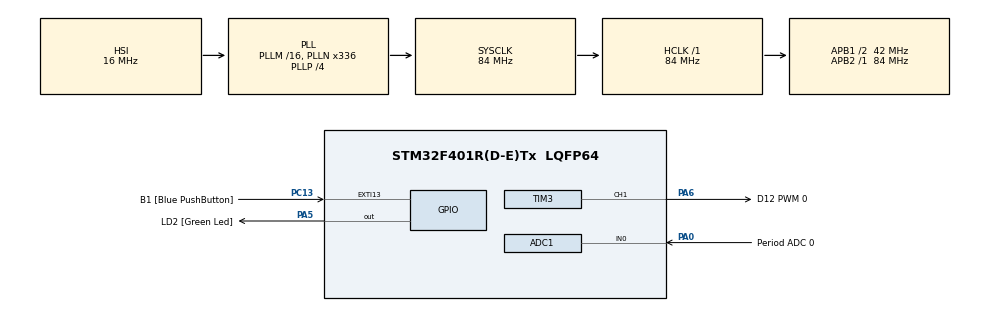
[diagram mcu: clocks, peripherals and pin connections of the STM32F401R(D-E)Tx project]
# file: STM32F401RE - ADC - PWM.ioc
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ADC1.Channel-0\#ChannelRegularConversion=ADC_CHANNEL_0
ADC1.ContinuousConvMode=ENABLE
ADC1.DMAContinuousRequests=ENABLE
ADC1.InjNumberOfConversion=0
ADC1.NbrOfConversion=1
ADC1.NbrOfConversionFlag=1
ADC1.Rank-0\#ChannelRegularConversion=1
ADC1.SamplingTime-0\#ChannelRegularConversion=ADC_SAMPLETIME_480CYCLES
ADC1.ScanConvMode=ENABLE
ADC1.master=1
Dma.ADC1.0.Direction=DMA_PERIPH_TO_MEMORY
Dma.ADC1.0.FIFOMode=DMA_FIFOMODE_DISABLE
Dma.ADC1.0.Instance=DMA2_Stream0
Dma.ADC1.0.MemDataAlignment=DMA_MDATAALIGN_WORD
Dma.ADC1.0.MemInc=DMA_MINC_ENABLE
Dma.ADC1.0.Mode=DMA_CIRCULAR
Dma.ADC1.0.PeriphDataAlignment=DMA_PDATAALIGN_WORD
Dma.ADC1.0.PeriphInc=DMA_PINC_DISABLE
Dma.ADC1.0.Priority=DMA_PRIORITY_LOW
Dma.Request0=ADC1
Mcu.Family=STM32F4
Mcu.Name=STM32F401R(D-E)Tx
Mcu.Package=LQFP64
NVIC.DMA2_Stream0_IRQn=true\:0\:0\:false\:false\:true\:false\:true
NVIC.PriorityGroup=NVIC_PRIORITYGROUP_0
PA0-WKUP.GPIO_Label=Period ADC 0
PA0-WKUP.Signal=ADCx_IN0
PA13.GPIO_Label=TMS
PA13.Signal=SYS_JTMS-SWDIO
PA14.GPIO_Label=TCK
PA14.Signal=SYS_JTCK-SWCLK
PA2.GPIO_Label=USART_TX
PA2.GPIO_Mode=GPIO_MODE_AF_PP
PA2.GPIO_PuPd=GPIO_NOPULL
PA2.GPIO_Speed=GPIO_SPEED_FREQ_LOW
PA2.Signal=USART2_TX
PA3.GPIO_Label=USART_RX
PA3.GPIO_Mode=GPIO_MODE_AF_PP
PA3.GPIO_PuPd=GPIO_NOPULL
PA3.GPIO_Speed=GPIO_SPEED_FREQ_LOW
PA3.Signal=USART2_RX
PA5.GPIO_Label=LD2 [Green Led]
PA5.GPIO_Mode=GPIO_MODE_OUTPUT_PP
PA5.GPIO_PuPd=GPIO_NOPULL
PA5.GPIO_Speed=GPIO_SPEED_FREQ_LOW
PA5.Signal=GPIO_Output
PA6.GPIO_Label=D12 PWM 0
PA6.Signal=S_TIM3_CH1
PB3.GPIO_Label=SWO
PB3.Signal=SYS_JTDO-SWO
PC13-ANTI_TAMP.GPIO_Label=B1 [Blue PushButton]
PC13-ANTI_TAMP.GPIO_ModeDefaultEXTI=GPIO_MODE_IT_FALLING
PC13-ANTI_TAMP.GPIO_PuPd=GPIO_NOPULL
PC13-ANTI_TAMP.Signal=GPXTI13
PC14-OSC32_IN.Signal=RCC_OSC32_IN
PC15-OSC32_OUT.Signal=RCC_OSC32_OUT
PH0\ -\ OSC_IN.Signal=RCC_OSC_IN
PH1\ -\ OSC_OUT.Signal=RCC_OSC_OUT
ProjectManager.HeapSize=0x200
ProjectManager.StackSize=0x400
ProjectManager.TargetToolchain=TrueSTUDIO
RCC.AHBFreq_Value=84000000
RCC.APB1CLKDivider=RCC_HCLK_DIV2
RCC.APB1Freq_Value=42000000
RCC.APB1TimFreq_Value=84000000
RCC.APB2Freq_Value=84000000
RCC.APB2TimFreq_Value=84000000
RCC.CortexFreq_Value=84000000
RCC.HCLKFreq_Value=84000000
RCC.HSE_VALUE=8000000
RCC.HSI_VALUE=16000000
RCC.LSE_VALUE=32768
RCC.PLLN=336
RCC.PLLP=RCC_PLLP_DIV4
RCC.PLLQ=7
RCC.SYSCLKFreq_VALUE=84000000
RCC.SYSCLKSource=RCC_SYSCLKSOURCE_PLLCLK
RCC.VCOOutputFreq_Value=336000000
SH.ADCx_IN0.0=ADC1_IN0,IN0
SH.S_TIM3_CH1.0=TIM3_CH1,PWM Generation1 CH1
TIM3.Channel-PWM\ Generation1\ CH1=TIM_CHANNEL_1
TIM3.Period=4095
TIM3.Prescaler=84
TIM3.Pulse-PWM\ Generation1\ CH1=2000
VP_TIM3_VS_ClockSourceINT.Mode=Internal
board=NUCLEO-F401RE

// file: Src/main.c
/* USER CODE BEGIN Header */
/**
  ******************************************************************************
  * @file           : main.c
  * @brief          : Main program body
  ******************************************************************************
  * @attention
  *
  * <h2><center>&copy; Copyright (c) 2019 STMicroelectronics.
  * All rights reserved.</center></h2>
  *
  * This software component is licensed by ST under BSD 3-Clause license,
  * the "License"; You may not use this file except in compliance with the
  * License. You may obtain a copy of the License at:
  *                        opensource.org/licenses/BSD-3-Clause
  *
  ******************************************************************************
  */
/* USER CODE END Header */

#include "main.h"

ADC_HandleTypeDef hadc1;
DMA_HandleTypeDef hdma_adc1;

TIM_HandleTypeDef htim3;

void SystemClock_Config(void);
static void MX_GPIO_Init(void);
static void MX_DMA_Init(void);
static void MX_ADC1_Init(void);
static void MX_TIM3_Init(void);

/* USER CODE BEGIN 0 */

/*
 * Store array for ADC values
 */
volatile uint32_t adcInputs[1];

/* USER CODE END 0 */

int main(void)
{

  /* MCU Configuration--------------------------------------------------------*/

  /* Reset of all peripherals, Initializes the Flash interface and the Systick. */
  HAL_Init();

  /* Configure the system clock */
  SystemClock_Config();

  /* Initialize all configured peripherals */
  MX_GPIO_Init();
  MX_DMA_Init();
  MX_ADC1_Init();
  MX_TIM3_Init();
  /* USER CODE BEGIN 2 */

  /*
   * Start all the PWM channels
   */
  HAL_TIM_PWM_Start(&htim3, TIM_CHANNEL_1);

  /*
   * Start ADC
   */
  HAL_ADC_Start_DMA(&hadc1, (uint32_t *) adcInputs, 1);

  /* USER CODE END 2 */

  /* Infinite loop */
  while (1)
  {
	  htim3.Instance->CCR1 = adcInputs[0];
  }
}

void SystemClock_Config(void)
{
  RCC_OscInitTypeDef RCC_OscInitStruct = {0};
  RCC_ClkInitTypeDef RCC_ClkInitStruct = {0};

  /** Configure the main internal regulator output voltage
  */
  __HAL_RCC_PWR_CLK_ENABLE();
  __HAL_PWR_VOLTAGESCALING_CONFIG(PWR_REGULATOR_VOLTAGE_SCALE2);
  /** Initializes the CPU, AHB and APB busses clocks
  */
  RCC_OscInitStruct.OscillatorType = RCC_OSCILLATORTYPE_HSI;
  RCC_OscInitStruct.HSIState = RCC_HSI_ON;
  RCC_OscInitStruct.HSICalibrationValue = RCC_HSICALIBRATION_DEFAULT;
  RCC_OscInitStruct.PLL.PLLState = RCC_PLL_ON;
  RCC_OscInitStruct.PLL.PLLSource = RCC_PLLSOURCE_HSI;
  RCC_OscInitStruct.PLL.PLLM = 16;
  RCC_OscInitStruct.PLL.PLLN = 336;
  RCC_OscInitStruct.PLL.PLLP = RCC_PLLP_DIV4;
  RCC_OscInitStruct.PLL.PLLQ = 7;
  if (HAL_RCC_OscConfig(&RCC_OscInitStruct) != HAL_OK)
  {
    Error_Handler();
  }
  /** Initializes the CPU, AHB and APB busses clocks
  */
  RCC_ClkInitStruct.ClockType = RCC_CLOCKTYPE_HCLK|RCC_CLOCKTYPE_SYSCLK
                              |RCC_CLOCKTYPE_PCLK1|RCC_CLOCKTYPE_PCLK2;
  RCC_ClkInitStruct.SYSCLKSource = RCC_SYSCLKSOURCE_PLLCLK;
  RCC_ClkInitStruct.AHBCLKDivider = RCC_SYSCLK_DIV1;
  RCC_ClkInitStruct.APB1CLKDivider = RCC_HCLK_DIV2;
  RCC_ClkInitStruct.APB2CLKDivider = RCC_HCLK_DIV1;

  if (HAL_RCC_ClockConfig(&RCC_ClkInitStruct, FLASH_LATENCY_2) != HAL_OK)
  {
    Error_Handler();
  }
}

static void MX_ADC1_Init(void)
{

  ADC_ChannelConfTypeDef sConfig = {0};

  /** Configure the global features of the ADC (Clock, Resolution, Data Alignment and number of conversion)
  */
  hadc1.Instance = ADC1;
  hadc1.Init.ClockPrescaler = ADC_CLOCK_SYNC_PCLK_DIV4;
  hadc1.Init.Resolution = ADC_RESOLUTION_12B;
  hadc1.Init.ScanConvMode = ENABLE;
  hadc1.Init.ContinuousConvMode = ENABLE;
  hadc1.Init.DiscontinuousConvMode = DISABLE;
  hadc1.Init.ExternalTrigConvEdge = ADC_EXTERNALTRIGCONVEDGE_NONE;
  hadc1.Init.ExternalTrigConv = ADC_SOFTWARE_START;
  hadc1.Init.DataAlign = ADC_DATAALIGN_RIGHT;
  hadc1.Init.NbrOfConversion = 1;
  hadc1.Init.DMAContinuousRequests = ENABLE;
  hadc1.Init.EOCSelection = ADC_EOC_SINGLE_CONV;
  if (HAL_ADC_Init(&hadc1) != HAL_OK)
  {
    Error_Handler();
  }
  /** Configure for the selected ADC regular channel its corresponding rank in the sequencer and its sample time.
  */
  sConfig.Channel = ADC_CHANNEL_0;
  sConfig.Rank = 1;
  sConfig.SamplingTime = ADC_SAMPLETIME_480CYCLES;
  if (HAL_ADC_ConfigChannel(&hadc1, &sConfig) != HAL_OK)
  {
    Error_Handler();
  }

}

static void MX_TIM3_Init(void)
{

  TIM_ClockConfigTypeDef sClockSourceConfig = {0};
  TIM_MasterConfigTypeDef sMasterConfig = {0};
  TIM_OC_InitTypeDef sConfigOC = {0};

  htim3.Instance = TIM3;
  htim3.Init.Prescaler = 84;
  htim3.Init.CounterMode = TIM_COUNTERMODE_UP;
  htim3.Init.Period = 4095;
  htim3.Init.ClockDivision = TIM_CLOCKDIVISION_DIV1;
  htim3.Init.AutoReloadPreload = TIM_AUTORELOAD_PRELOAD_DISABLE;
  if (HAL_TIM_Base_Init(&htim3) != HAL_OK)
  {
    Error_Handler();
  }
  sClockSourceConfig.ClockSource = TIM_CLOCKSOURCE_INTERNAL;
  if (HAL_TIM_ConfigClockSource(&htim3, &sClockSourceConfig) != HAL_OK)
  {
    Error_Handler();
  }
  if (HAL_TIM_PWM_Init(&htim3) != HAL_OK)
  {
    Error_Handler();
  }
  sMasterConfig.MasterOutputTrigger = TIM_TRGO_RESET;
  sMasterConfig.MasterSlaveMode = TIM_MASTERSLAVEMODE_DISABLE;
  if (HAL_TIMEx_MasterConfigSynchronization(&htim3, &sMasterConfig) != HAL_OK)
  {
    Error_Handler();
  }
  sConfigOC.OCMode = TIM_OCMODE_PWM1;
  sConfigOC.Pulse = 2000;
  sConfigOC.OCPolarity = TIM_OCPOLARITY_HIGH;
  sConfigOC.OCFastMode = TIM_OCFAST_DISABLE;
  if (HAL_TIM_PWM_ConfigChannel(&htim3, &sConfigOC, TIM_CHANNEL_1) != HAL_OK)
  {
    Error_Handler();
  }
  HAL_TIM_MspPostInit(&htim3);

}

static void MX_DMA_Init(void)
{
  /* DMA controller clock enable */
  __HAL_RCC_DMA2_CLK_ENABLE();

  /* DMA interrupt init */
  /* DMA2_Stream0_IRQn interrupt configuration */
  HAL_NVIC_SetPriority(DMA2_Stream0_IRQn, 0, 0);
  HAL_NVIC_EnableIRQ(DMA2_Stream0_IRQn);

}

static void MX_GPIO_Init(void)
{
  GPIO_InitTypeDef GPIO_InitStruct = {0};

  /* GPIO Ports Clock Enable */
  __HAL_RCC_GPIOC_CLK_ENABLE();
  __HAL_RCC_GPIOH_CLK_ENABLE();
  __HAL_RCC_GPIOA_CLK_ENABLE();
  __HAL_RCC_GPIOB_CLK_ENABLE();

  /*Configure GPIO pin Output Level */
  HAL_GPIO_WritePin(LD2_GPIO_Port, LD2_Pin, GPIO_PIN_RESET);

  /*Configure GPIO pin : B1_Pin */
  GPIO_InitStruct.Pin = B1_Pin;
  GPIO_InitStruct.Mode = GPIO_MODE_IT_FALLING;
  GPIO_InitStruct.Pull = GPIO_NOPULL;
  HAL_GPIO_Init(B1_GPIO_Port, &GPIO_InitStruct);

  /*Configure GPIO pins : USART_TX_Pin USART_RX_Pin */
  GPIO_InitStruct.Pin = USART_TX_Pin|USART_RX_Pin;
  GPIO_InitStruct.Mode = GPIO_MODE_AF_PP;
  GPIO_InitStruct.Pull = GPIO_NOPULL;
  GPIO_InitStruct.Speed = GPIO_SPEED_FREQ_LOW;
  GPIO_InitStruct.Alternate = GPIO_AF7_USART2;
  HAL_GPIO_Init(GPIOA, &GPIO_InitStruct);

  /*Configure GPIO pin : LD2_Pin */
  GPIO_InitStruct.Pin = LD2_Pin;
  GPIO_InitStruct.Mode = GPIO_MODE_OUTPUT_PP;
  GPIO_InitStruct.Pull = GPIO_NOPULL;
  GPIO_InitStruct.Speed = GPIO_SPEED_FREQ_LOW;
  HAL_GPIO_Init(LD2_GPIO_Port, &GPIO_InitStruct);

}

void Error_Handler(void)
{
}

/************************ (C) COPYRIGHT STMicroelectronics *****END OF FILE****/
